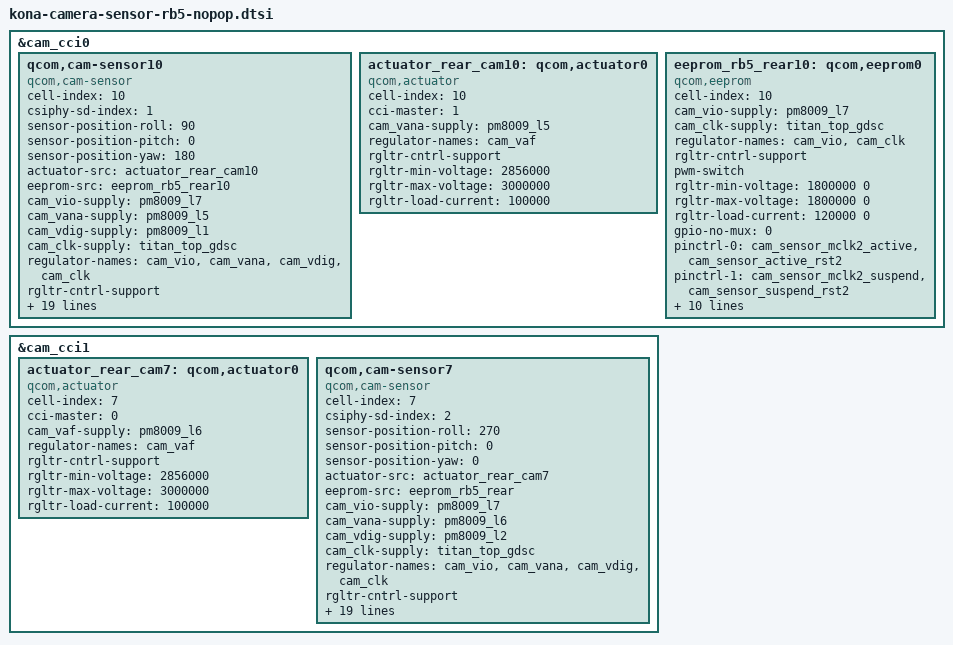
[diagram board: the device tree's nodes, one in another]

&cam_cci0 {
	qcom,cam-sensor10 {
		cell-index = <10>;
		compatible = "qcom,cam-sensor";
		csiphy-sd-index = <1>;
		sensor-position-roll = <90>;
		sensor-position-pitch = <0>;
		sensor-position-yaw = <180>;
		actuator-src = <&actuator_rear_cam10>;
		eeprom-src = <&eeprom_rb5_rear10>;
		cam_vio-supply = <&pm8009_l7>;
		cam_vana-supply = <&pm8009_l5>;
		cam_vdig-supply = <&pm8009_l1>;
		cam_clk-supply = <&titan_top_gdsc>;
		regulator-names = "cam_vio", "cam_vana", "cam_vdig", "cam_clk";
		rgltr-cntrl-support;
		pwm-switch;
		rgltr-min-voltage = <1800000 2800000 1104000 0>;
		rgltr-max-voltage = <1800000 3000000 1104000 0>;
		rgltr-load-current = <120000 800000 1104000 0>;
		gpio-no-mux = <0>;
		pinctrl-names = "cam_default", "cam_suspend";
		pinctrl-0 = <&cam_sensor_mclk1_active
				&cam_sensor_active_rear_aux>;
		pinctrl-1 = <&cam_sensor_mclk1_suspend
				&cam_sensor_suspend_rear_aux>;
		gpios = <&tlmm 95 0>,
			<&tlmm 92 0>;
		gpio-reset = <1>;
		gpio-req-tbl-num = <0 1>;
		gpio-req-tbl-flags = <1 0>;
		gpio-req-tbl-label = "CAMIF_MCLK0",
					"CAM_RESET0";
		sensor-mode = <0>;
		cci-master = <1>;
		status = "ok";
		clocks = <&clock_camcc CAM_CC_MCLK1_CLK>;
		clock-names = "cam_clk";
		clock-cntl-level = "turbo";
		clock-rates = <24000000>;
	};

	actuator_rear_cam10: qcom,actuator0 {
		cell-index = <10>;
		compatible = "qcom,actuator";
		cci-master = <1>;
		cam_vana-supply = <&pm8009_l5>;
		regulator-names = "cam_vaf";
		rgltr-cntrl-support;
		rgltr-min-voltage = <2856000>;
		rgltr-max-voltage = <3000000>;
		rgltr-load-current = <100000>;
	};

	eeprom_rb5_rear10: qcom,eeprom0 {
		cell-index = <10>;
		compatible = "qcom,eeprom";
		cam_vio-supply = <&pm8009_l7>;
		cam_clk-supply = <&titan_top_gdsc>;
		regulator-names = "cam_vio", "cam_clk";
		rgltr-cntrl-support;
		pwm-switch;
		rgltr-min-voltage = <1800000 0>;
		rgltr-max-voltage = <1800000 0>;
		rgltr-load-current = <120000 0>;
		gpio-no-mux = <0>;
		pinctrl-names = "cam_default", "cam_suspend";
		pinctrl-0 = <&cam_sensor_mclk2_active
				 &cam_sensor_active_rst2>;
		pinctrl-1 = <&cam_sensor_mclk2_suspend
				 &cam_sensor_suspend_rst2>;
		gpios = <&tlmm 96 0>,
			<&tlmm 78 0>;
		gpio-reset = <1>;
		gpio-req-tbl-num = <0 1>;
		gpio-req-tbl-flags = <1 0>;
		gpio-req-tbl-label = "CAMIF_MCLK2",
					"CAM_RESET2";
		sensor-mode = <0>;
		cci-master = <1>;
		status = "ok";
		clocks = <&clock_camcc CAM_CC_MCLK2_CLK>;
		clock-names = "cam_clk";
		clock-cntl-level = "turbo";
		clock-rates = <24000000>;
	};
};

&cam_cci1 {
	actuator_rear_cam7: qcom,actuator0 {
		cell-index = <7>;
		compatible = "qcom,actuator";
		cci-master = <0>;
		cam_vaf-supply = <&pm8009_l6>;
		regulator-names = "cam_vaf";
		rgltr-cntrl-support;
		rgltr-min-voltage = <2856000>;
		rgltr-max-voltage = <3000000>;
		rgltr-load-current = <100000>;
	};

	qcom,cam-sensor7 {
		cell-index = <7>;
		compatible = "qcom,cam-sensor";
		csiphy-sd-index = <2>;
		sensor-position-roll = <270>;
		sensor-position-pitch = <0>;
		sensor-position-yaw = <0>;
		actuator-src = <&actuator_rear_cam7>;
		eeprom-src = <&eeprom_rb5_rear>;
		cam_vio-supply = <&pm8009_l7>;
		cam_vana-supply = <&pm8009_l6>;
		cam_vdig-supply = <&pm8009_l2>;
		cam_clk-supply = <&titan_top_gdsc>;
		regulator-names = "cam_vio", "cam_vana", "cam_vdig", "cam_clk";
		rgltr-cntrl-support;
		pwm-switch;
		rgltr-min-voltage = <1800000 2800000 1200000 0>;
		rgltr-max-voltage = <1800000 3000000 1200000 0>;
		rgltr-load-current = <120000 800000 1200000 0>;
		gpio-no-mux = <0>;
		pinctrl-names = "cam_default", "cam_suspend";
		pinctrl-0 = <&cam_sensor_mclk2_active
				 &cam_sensor_active_rst2>;
		pinctrl-1 = <&cam_sensor_mclk2_suspend
				 &cam_sensor_suspend_rst2>;
		gpios = <&tlmm 96 0>,
			<&tlmm 78 0>;
		gpio-reset = <1>;
		gpio-req-tbl-num = <0 1>;
		gpio-req-tbl-flags = <1 0>;
		gpio-req-tbl-label = "CAMIF_MCLK2",
					"CAM_RESET2";
		sensor-mode = <0>;
		cci-master = <0>;
		status = "ok";
		clocks = <&clock_camcc CAM_CC_MCLK2_CLK>;
		clock-names = "cam_clk";
		clock-cntl-level = "turbo";
		clock-rates = <24000000>;
	};
};
